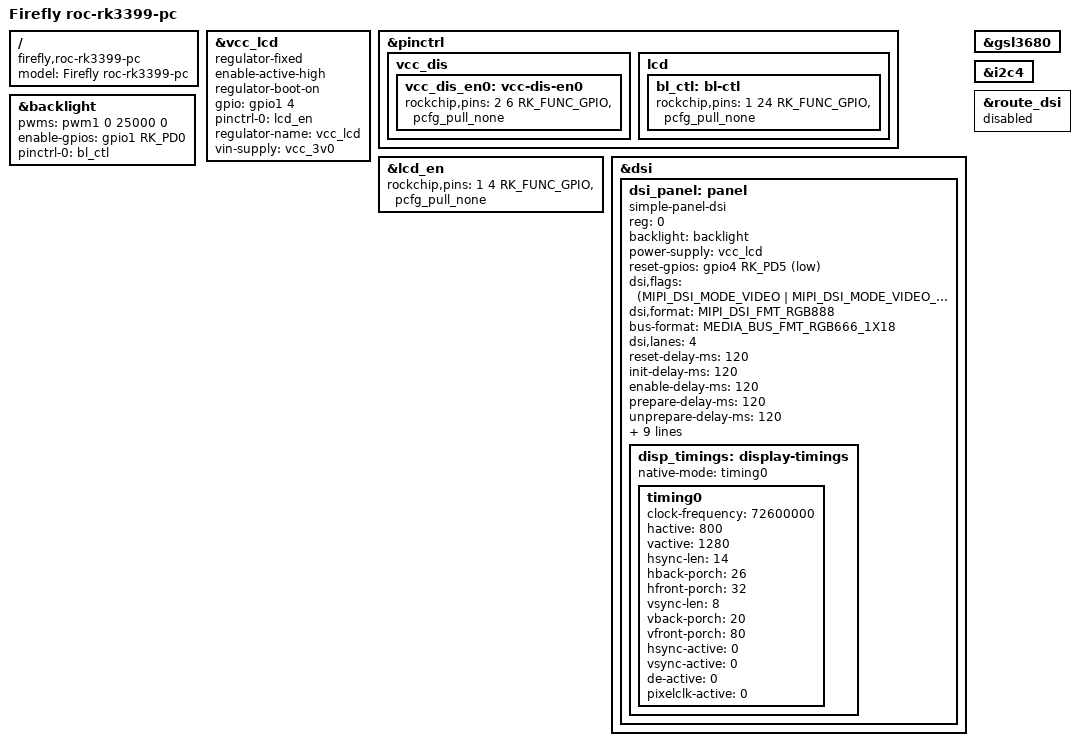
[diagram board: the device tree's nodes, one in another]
/dts-v1/;
#include "rk3399-roc-pc.dtsi"

/ {
	model = "Firefly roc-rk3399-pc";
	compatible = "firefly,roc-rk3399-pc", "rockchip,rk3399";

};

&vcc_lcd{
		compatible = "regulator-fixed";
		enable-active-high;
		regulator-boot-on;
		gpio = <&gpio1 4 GPIO_ACTIVE_HIGH>;
		pinctrl-names = "default";
		pinctrl-0 = <&lcd_en>;
		regulator-name = "vcc_lcd";
		vin-supply = <&vcc_3v0>;
};

&pinctrl {
	vcc_dis {
		vcc_dis_en0: vcc-dis-en0 {
			rockchip,pins =
				<2 6 RK_FUNC_GPIO &pcfg_pull_none>;
		};
	};
    lcd {
		bl_ctl: bl-ctl  {
			rockchip,pins = <1 24 RK_FUNC_GPIO &pcfg_pull_none>;
		};

	};
};

&lcd_en{
	rockchip,pins = <1 4 RK_FUNC_GPIO &pcfg_pull_none>;
};

&backlight {
	pwms = <&pwm1 0 25000 0>;
	enable-gpios = <&gpio1 RK_PD0 GPIO_ACTIVE_HIGH>;
	pinctrl-0 = <&bl_ctl>;
    status = "okay";
};

//mipi
&dsi {
	status = "okay";
	//status = "okay";
	dsi_panel: panel {
		compatible ="simple-panel-dsi";
		reg = <0>;
		backlight = <&backlight>;
		power-supply = <&vcc_lcd>;
        reset-gpios = <&gpio4 RK_PD5 GPIO_ACTIVE_LOW>;
		dsi,flags = <(MIPI_DSI_MODE_VIDEO | MIPI_DSI_MODE_VIDEO_BURST | MIPI_DSI_MODE_LPM)>;
		dsi,format = <MIPI_DSI_FMT_RGB888>;
		bus-format = <MEDIA_BUS_FMT_RGB666_1X18>;
		dsi,lanes = <4>;
		reset-delay-ms = <120>;
		init-delay-ms = <120>;
		enable-delay-ms = <120>;
		prepare-delay-ms = <120>;
        unprepare-delay-ms = <120>;
        disable-delay-ms = <120>;
//		status = "okay";
        size,width = <120>;
		size,height = <170>;

		status = "okay";

		width-mm = <135>;
		height-mm = <217>;

        panel-init-sequence = [
			05 78 01 11
			05 32 01 29
		];

		panel-exit-sequence = [
			05 05 01 28
			05 78 01 10
		];

		disp_timings: display-timings {
			native-mode = <&timing0>;

			timing0: timing0 {
				clock-frequency = <72600000>;//<80000000>;
				hactive = <800>;//<768>;
				vactive = <1280>;
				hsync-len = <14>;   //20, 50,10
				hback-porch = <26>; //50, 56,10
				hfront-porch = <32>;//50, 30,180
				vsync-len = <8>;//4
				vback-porch = <20>;//4
				vfront-porch = <80>;//8
				hsync-active = <0>;
				vsync-active = <0>;
				de-active = <0>;
				pixelclk-active = <0>;
			};
		};
	};
};

//TF
&gsl3680 {
	status = "okay";
};
&i2c4 {
	status = "okay";
};
//boot logo for MIPI screen
&route_dsi {
	status = "disabled";
};
